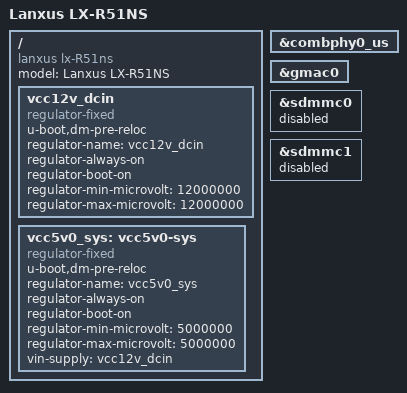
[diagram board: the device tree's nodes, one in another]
// SPDX-License-Identifier: (GPL-2.0+ OR MIT)
/*
 * Copyright (c) 2021 Rockchip Electronics Co., Ltd.
 *
 */

/dts-v1/;
#include <dt-bindings/input/input.h>
#include "rk3568.dtsi"
#include "rk3568-u-boot.dtsi"

/ {
	model = "Lanxus LX-R51NS";
	compatible = "lanxus lx-R51ns", "rockchip,rk3568";

	vcc12v_dcin: vcc12v_dcin {
		u-boot,dm-pre-reloc;
		compatible = "regulator-fixed";
		regulator-name = "vcc12v_dcin";
		regulator-always-on;
		regulator-boot-on;
		regulator-min-microvolt = <12000000>;
		regulator-max-microvolt = <12000000>;
	};
	
	vcc5v0_sys: vcc5v0-sys {
		u-boot,dm-pre-reloc;
		compatible = "regulator-fixed";
		regulator-name = "vcc5v0_sys";
		regulator-always-on;
		regulator-boot-on;
		regulator-min-microvolt = <5000000>;
		regulator-max-microvolt = <5000000>;
		vin-supply = <&vcc12v_dcin>;
	};
};

&combphy0_us {
	status = "okay";
};

&gmac0 {
	status = "okay";
};

&sdmmc0 {
	status = "disabled";
};

&sdmmc1 {
	status = "disabled";
};
